# AVR128DA64S register map
Vendor: Atmel; File version: 1.0
CPU: other r0p0, little endian, no MPU, no FPU, 4 interrupt priority bits
Registers are 8-bit, read-write, reset 0x0 unless marked. A register's access mark holds for its fields unless they carry their own. Offsets are from the block's base; [hi:lo] are bit positions; {n}, {i} and the like mark numbered series.

## SIGROW — Signature row
Base 0x00801100
{0x0+i} DEVICEID{i} ro (i=0..2) — Device ID Byte {i}
0x04 TEMPSENSE0 16-bit ro (reset mask 0xFF) — Temperature Calibration 0
0x06 TEMPSENSE1 16-bit ro (reset mask 0xFF) — Temperature Calibration 1
{0x10+i} SERNUM{i} ro (i=0..5) — LOTNUM{i}
0x16 SERNUM6 ro — RANDOM
0x17 SERNUM7 ro — SCRIBE
0x18 SERNUM8 ro — XPOS0
0x19 SERNUM9 ro — XPOS1
0x1A SERNUM10 ro — YPOS0
0x1B SERNUM11 ro — YPOS1
{0x10+i} SERNUM{i} ro (i=12..15) — RES{i-12}

## SLPCTRL — Sleep Controller
Base 0x00800050
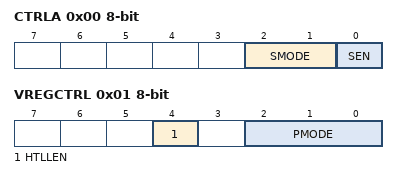
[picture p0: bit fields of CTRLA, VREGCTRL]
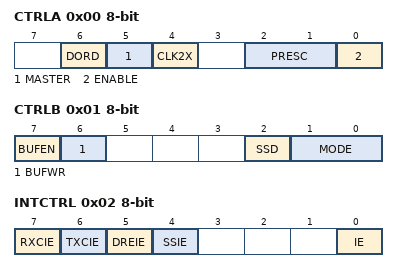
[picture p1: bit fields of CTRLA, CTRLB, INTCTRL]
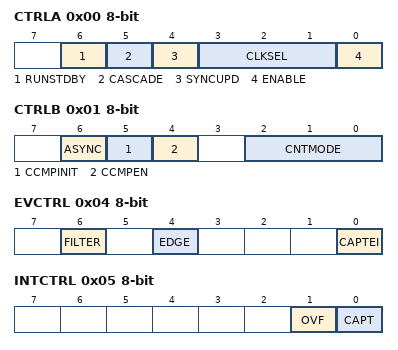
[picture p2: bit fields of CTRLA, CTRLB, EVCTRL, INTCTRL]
0x00 CTRLA — Control A
  [2:1] SMODE — Sleep mode
    0=IDLE (Idle mode); 1=STDBY (Standby Mode); 2=PDOWN (Power-down Mode)
  [0] SEN — Sleep enable
0x01 VREGCTRL — Control B
  [4] HTLLEN — High Temperature Low Leakage Enable
    0=OFF (Disabled); 1=ON (Enabled)
  [2:0] PMODE — Performance Mode
    0=AUTO; 1=FULL

## SPI0 — Serial Peripheral Interface
Base 0x00800940
Same registers: SPI1 0x00800960
0x00 CTRLA — Control A
  [6] DORD — Data Order Setting
  [5] MASTER — Host Operation Enable
  [4] CLK2X — Enable Double Speed
  [2:1] PRESC — Prescaler
    0=DIV4 (CLK_PER / 4); 1=DIV16 (CLK_PER / 16); 2=DIV64 (CLK_PER / 64); 3=DIV128 (CLK_PER / 128)
  [0] ENABLE — Enable Module
0x01 CTRLB — Control B
  [7] BUFEN — Buffer Mode Enable
  [6] BUFWR — Buffer Mode Wait for Receive
  [2] SSD — SPI Select Disable
  [1:0] MODE — SPI Mode
    {v}=SPI Mode {v} (v=0..3)
0x02 INTCTRL — Interrupt Control
  [7] RXCIE — Receive Complete Interrupt Enable
  [6] TXCIE — Transfer Complete Interrupt Enable
  [5] DREIE — Data Register Empty Interrupt Enable
  [4] SSIE — SPI Select Trigger Interrupt Enable
  [0] IE — Interrupt Enable
0x03 INTFLAGS — Interrupt Flags
  [7] IF — Interrupt Flag
  [7] RXCIF — Receive Complete Interrupt Flag
  [6] TXCIF — Transfer Complete Interrupt Flag
  [6] WRCOL — Write Collision
  [5] DREIF — Data Register Empty Interrupt Flag
  [4] SSIF — SPI Select Trigger Interrupt Flag
  [0] BUFOVF — Buffer Overflow
0x04 DATA

## SYSCFG — System Configuration Registers
Base 0x00800F01
0x00 REVID ro — Revision ID
0x17 OCDMCTRL — OCD Message Control
0x18 OCDMSTATUS — OCD Message Status
  [0] OCDMR — OCD Message Read

## TCB0 — 16-bit Timer Type B
Base 0x00800B00
Same registers: TCB1 0x00800B10, TCB2 0x00800B20, TCB3 0x00800B30, TCB4 0x00800B40
0x00 CTRLA — Control A
  [6] RUNSTDBY — Run Standby
  [5] CASCADE — Cascade two timers
  [4] SYNCUPD — Synchronize Update
  [3:1] CLKSEL — Clock Select
    0=DIV1 (CLK_PER); 1=DIV2 (CLK_PER/2); 2=TCA0 (Use CLK_TCA from TCA0); 3=TCA1 (Use CLK_TCA from TCA1); 7=EVENT (Count on event edge)
  [0] ENABLE
0x01 CTRLB — Control Register B
  [6] ASYNC — Asynchronous Enable
  [5] CCMPINIT — Pin Initial State
  [4] CCMPEN — Pin Output Enable
  [2:0] CNTMODE — Timer Mode
    0=INT (Periodic Interrupt); 1=TIMEOUT (Periodic Timeout); 2=CAPT (Input Capture Event); 3=FRQ (Input Capture Frequency measurement); 4=PW (Input Capture Pulse-Width measurement); 5=FRQPW (Input Capture Frequency and Pulse-Width measurement); 6=SINGLE (Single Shot); 7=PWM8 (8-bit PWM)
0x04 EVCTRL — Event Control
  [6] FILTER — Input Capture Noise Cancellation Filter
  [4] EDGE — Event Edge
  [0] CAPTEI — Event Input Enable
0x05 INTCTRL — Interrupt Control
  [1] OVF — Overflow
  [0] CAPT — Capture or Timeout
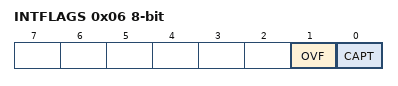
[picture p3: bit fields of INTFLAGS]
0x06 INTFLAGS — Interrupt Flags
  [1] OVF — Overflow
  [0] CAPT — Capture or Timeout
0x07 STATUS ro
  [0] RUN
0x08 DBGCTRL — Debug Control
  [0] DBGRUN — Debug Run
0x09 TEMP — Temporary Value
0x0A CNT 16-bit (reset mask 0xFF) — Count
0x0C CCMP 16-bit (reset mask 0xFF) — Compare or Capture
